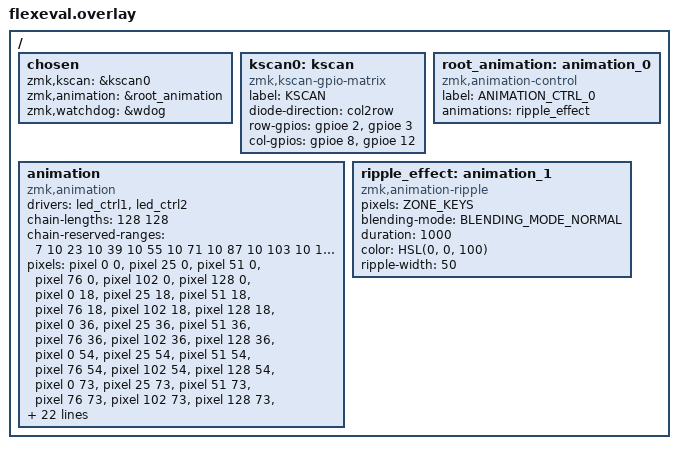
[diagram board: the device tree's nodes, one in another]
/*
 * Copyright 2023 Daniel DeGrasse
 *
 * SPDX-License-Identifier: Apache-2.0
 */

#include <animation.dtsi>
#include <dt-bindings/zmk/animation.h>
#include <dt-bindings/zmk/animation_compose.h>

#define DUMMY_PIXEL &pixel 0 0
/*
 * Key zone definition. These indices are used by the animation driver to
 * determine which keys to render pixels for. Since we utilize the
 * chain-reserved-ranges property, the zone for all keys has a 1:1 mapping
 * with the pixel list
 */
#define ZONE_KEYS 0 1 2 3 4 5 6 7 8 9 10 11 12 13 14 15 16 17 18 19 20 21 22 \
		23 24 25 26 27 28 29 30 31 32 33 34 35 36 37 38 39 40 41 42 \
		43 44 45 46 47 48 49 50 51 52 53 54 55 56 57 58 59 60 61 62 \
		63 64 65 66 67 68 69 70 71 72 73 74 75 76 77 78 79 80 81 82 \
		83 84 85 86 87 88 89 90 91 92 93 94 95

/ {
	chosen {
		zmk,kscan = &kscan0;
		zmk,animation = &root_animation;
		zmk,watchdog = &wdog;
	};

	kscan0: kscan {
		compatible = "zmk,kscan-gpio-matrix";
		label = "KSCAN";
		diode-direction = "col2row";
		row-gpios = <&gpioe 2 (GPIO_ACTIVE_HIGH | GPIO_PULL_DOWN)>,
		 	<&gpioe 3 (GPIO_ACTIVE_HIGH | GPIO_PULL_DOWN)>;
		col-gpios = <&gpioe 8 GPIO_ACTIVE_HIGH>,
		 	<&gpioe 12 GPIO_ACTIVE_HIGH>;
	};

	/*
	 * Pixel definitions are given with coordinates from 0-255.
	 * since we have two led controllers we give each block of 118 pixels
	 * sequentially.
	 */

	animation {
		compatible = "zmk,animation";
		drivers = <&led_ctrl1 &led_ctrl2>;
		chain-lengths = <128 128>;
		chain-reserved-ranges = <7 10 23 10 39 10 55 10 71 10 87 10
					103 10 119 10 135 10 151 10 167 10
					183 10 199 10 215 10 231 10 247 10>;
		pixels = /* Row 1 */
			<&pixel 0 0>,
			<&pixel 25 0>,
			<&pixel 51 0>,
			<&pixel 76 0>,
			<&pixel 102 0>,
			<&pixel 128 0>,
			/* Row 2 */
			<&pixel 0 18>,
			<&pixel 25 18>,
			<&pixel 51 18>,
			<&pixel 76 18>,
			<&pixel 102 18>,
			<&pixel 128 18>,
			/* Row 3 */
			<&pixel 0 36>,
			<&pixel 25 36>,
			<&pixel 51 36>,
			<&pixel 76 36>,
			<&pixel 102 36>,
			<&pixel 128 36>,
			/* Row 4 */
			<&pixel 0 54>,
			<&pixel 25 54>,
			<&pixel 51 54>,
			<&pixel 76 54>,
			<&pixel 102 54>,
			<&pixel 128 54>,
			/* Row 5 */
			<&pixel 0 73>,
			<&pixel 25 73>,
			<&pixel 51 73>,
			<&pixel 76 73>,
			<&pixel 102 73>,
			<&pixel 128 73>,
			/* Row 6 */
			<&pixel 0 91>,
			<&pixel 25 91>,
			<&pixel 51 91>,
			<&pixel 76 91>,
			<&pixel 102 91>,
			<&pixel 128 91>,
			/* Row 7 */
			<&pixel 0 109>,
			<&pixel 25 109>,
			<&pixel 51 109>,
			<&pixel 76 109>,
			<&pixel 102 109>,
			<&pixel 128 109>,
			/* Row 8 */
			<&pixel 0 128>,
			<&pixel 25 128>,
			<&pixel 51 128>,
			<&pixel 76 128>,
			<&pixel 102 128>,
			<&pixel 128 128>,
			/* Controller 2 */
			/* Row 1 */
			<&pixel 128 0>,
			<&pixel 153 0>,
			<&pixel 179 0>,
			<&pixel 204 0>,
			<&pixel 230 0>,
			<&pixel 255 0>,
			/* Row 2 */
			<&pixel 128 18>,
			<&pixel 153 18>,
			<&pixel 179 18>,
			<&pixel 204 18>,
			<&pixel 230 18>,
			<&pixel 255 18>,
			/* Row 3 */
			<&pixel 128 36>,
			<&pixel 153 36>,
			<&pixel 179 36>,
			<&pixel 204 36>,
			<&pixel 230 36>,
			<&pixel 255 36>,
			/* Row 4 */
			<&pixel 128 54>,
			<&pixel 153 54>,
			<&pixel 179 54>,
			<&pixel 204 54>,
			<&pixel 230 54>,
			<&pixel 255 54>,
			/* Row 5 */
			<&pixel 128 73>,
			<&pixel 153 73>,
			<&pixel 179 73>,
			<&pixel 204 73>,
			<&pixel 230 73>,
			<&pixel 255 73>,
			/* Row 6 */
			<&pixel 128 91>,
			<&pixel 153 91>,
			<&pixel 179 91>,
			<&pixel 204 91>,
			<&pixel 230 91>,
			<&pixel 255 91>,
			/* Row 7 */
			<&pixel 128 109>,
			<&pixel 153 109>,
			<&pixel 179 109>,
			<&pixel 204 109>,
			<&pixel 230 109>,
			<&pixel 255 109>,
			/* Row 8 */
			<&pixel 128 128>,
			<&pixel 153 128>,
			<&pixel 179 128>,
			<&pixel 204 128>,
			<&pixel 230 128>,
			<&pixel 255 128>;
	};

	root_animation: animation_0 {
		compatible = "zmk,animation-control";
		label = "ANIMATION_CTRL_0";
		animations = <&ripple_effect>;
	};

	ripple_effect: animation_1 {
		compatible = "zmk,animation-ripple";
		status = "okay";
		pixels = <ZONE_KEYS>;
		blending-mode = <BLENDING_MODE_NORMAL>;
		duration = <1000>;
		color = <HSL(0, 0, 100)>;
		ripple-width = <50>;
	};
};
